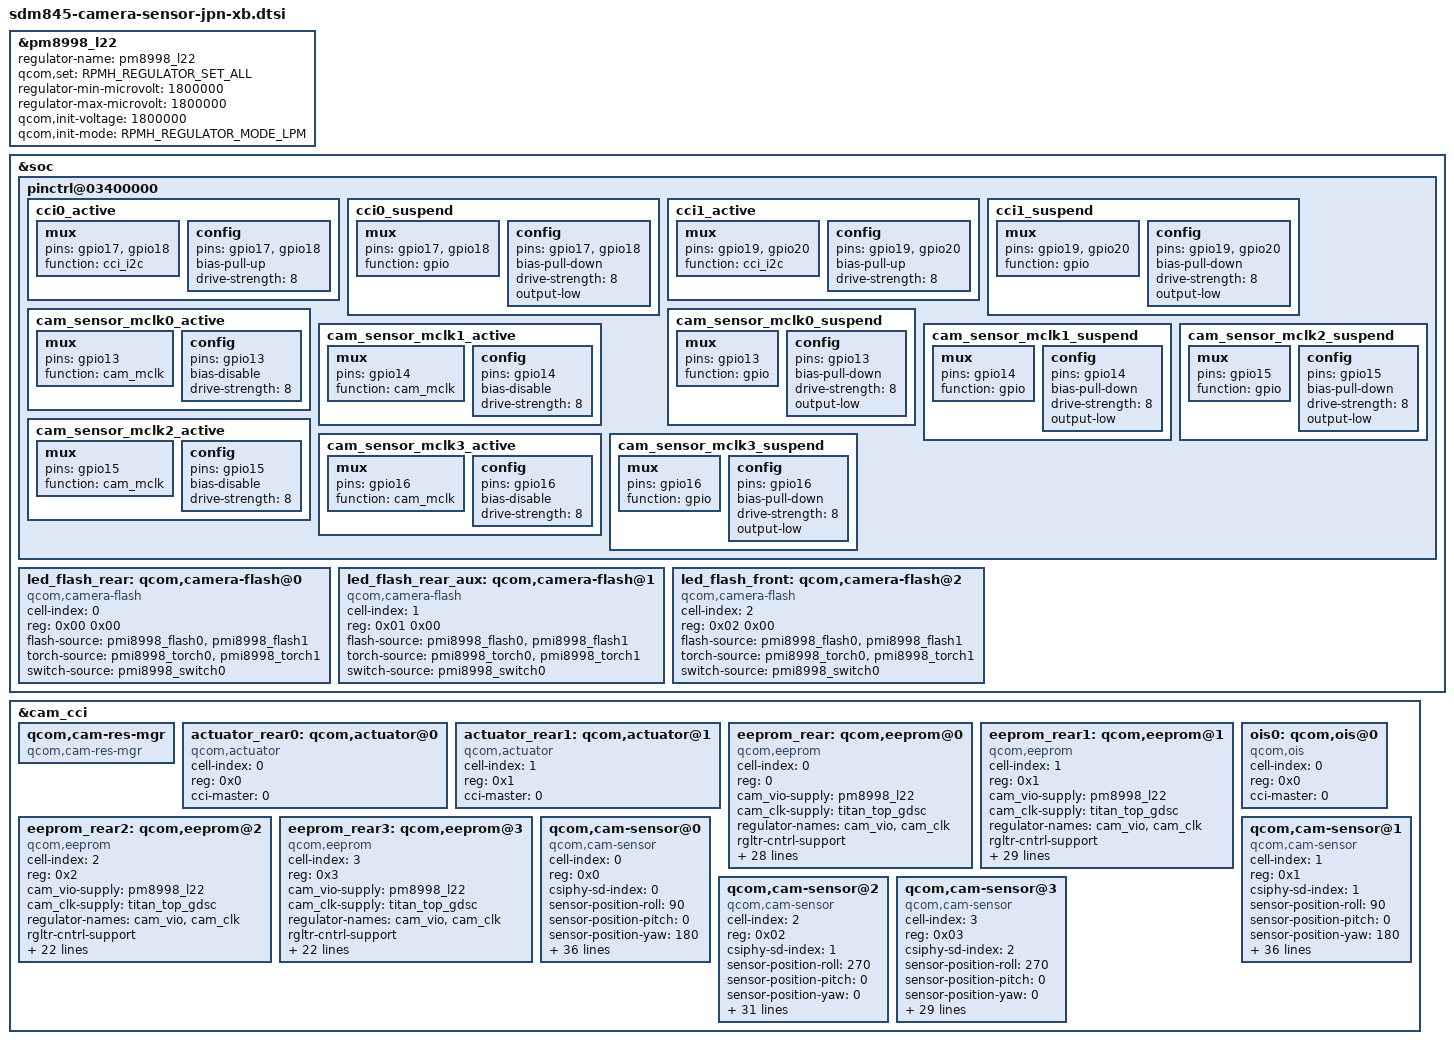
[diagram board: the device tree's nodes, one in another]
/*
 * Copyright (c) 2017, The Linux Foundation. All rights reserved.
 *
 * This program is free software; you can redistribute it and/or modify
 * it under the terms of the GNU General Public License version 2 and
 * only version 2 as published by the Free Software Foundation.
 *
 * This program is distributed in the hope that it will be useful,
 * but WITHOUT ANY WARRANTY; without even the implied warranty of
 * MERCHANTABILITY or FITNESS FOR A PARTICULAR PURPOSE. See the
 * GNU General Public License for more details.
 */

#include <dt-bindings/regulator/qcom,rpmh-regulator.h>

&pm8998_l22 {
	regulator-name = "pm8998_l22";
	qcom,set = <RPMH_REGULATOR_SET_ALL>;
	regulator-min-microvolt = <1800000>;
	regulator-max-microvolt = <1800000>;
	qcom,init-voltage = <1800000>;
	qcom,init-mode = <RPMH_REGULATOR_MODE_LPM>;
};

&soc {
	pinctrl@03400000 {
		cci0_active {
			mux {
				/* CLK, DATA */
				pins = "gpio17","gpio18"; // Only 2
				function = "cci_i2c";
			};

			config {
				pins = "gpio17","gpio18";
				bias-pull-up; /* PULL UP*/
				drive-strength = <8>; /* 2 MA */
			};
		};

		cci0_suspend {
			mux {
				/* CLK, DATA */
				pins = "gpio17","gpio18";
				function = "gpio";
			};

			config {
				pins = "gpio17","gpio18";
				bias-pull-down; /* PULL DOWN */
				drive-strength = <8>; /* 2 MA */
				output-low; /*HTC ADD*/
			};
		};

		cci1_active {
			mux {
				/* CLK, DATA */
				pins = "gpio19","gpio20";
				function = "cci_i2c";
			};

			config {
				pins = "gpio19","gpio20";
				bias-pull-up; /* PULL UP*/
				drive-strength = <8>; /* 2 MA */
			};
		};

		cci1_suspend {
			mux {
				/* CLK, DATA */
				pins = "gpio19","gpio20";
				function = "gpio";
			};

			config {
				pins = "gpio19","gpio20";
				bias-pull-down; /* PULL DOWN */
				drive-strength = <8>; /* 2 MA */
				output-low; /*HTC ADD*/
			};
		};

		cam_sensor_mclk0_active {
			/* MCLK0 */
			mux {
				/* CLK, DATA */
				pins = "gpio13";
				function = "cam_mclk";
			};

			config {
				pins = "gpio13";
				bias-disable; /* No PULL */
				drive-strength = <8>; /* 2 MA */
			};
		};

		cam_sensor_mclk0_suspend {
			/* MCLK0 */
			mux {
				/* CLK, DATA */
				pins = "gpio13";
				function = "gpio";
			};

			config {
				pins = "gpio13";
				bias-pull-down; /* PULL DOWN */
				drive-strength = <8>; /* 2 MA */
				output-low; /*HTC ADD*/
			};
		};

		cam_sensor_mclk1_active {
			/* MCLK1 */
			mux {
				/* CLK, DATA */
				pins = "gpio14";
				function = "cam_mclk";
			};

			config {
				pins = "gpio14";
				bias-disable; /* No PULL */
				drive-strength = <8>; /* 2 MA */
			};
		};

		cam_sensor_mclk1_suspend {
			/* MCLK1 */
			mux {
				/* CLK, DATA */
				pins = "gpio14";
				function = "gpio";
			};

			config {
				pins = "gpio14";
				bias-pull-down; /* PULL DOWN */
				drive-strength = <8>; /* 2 MA */
				output-low; /*HTC ADD*/
			};
		};
		cam_sensor_mclk2_active {
			/* MCLK2 */
			mux {
				/* CLK, DATA */
				pins = "gpio15";
				function = "cam_mclk";
			};

			config {
				pins = "gpio15";
				bias-disable; /* No PULL */
				drive-strength = <8>; /* 2 MA */
			};
		};

		cam_sensor_mclk2_suspend {
			/* MCLK2 */
			mux {
				/* CLK, DATA */
				pins = "gpio15";
				function = "gpio";
			};

			config {
				pins = "gpio15";
				bias-pull-down; /* PULL DOWN */
				drive-strength = <8>; /* 2 MA */
				output-low; /*HTC ADD*/
			};
		};
		cam_sensor_mclk3_active {
			/* MCLK3 */
			mux {
				pins = "gpio16";
				function = "cam_mclk";
			};

			config {
				pins = "gpio16";
				bias-disable; /* No PULL */
				drive-strength = <8>; /* 2 MA */
			};
		};
		cam_sensor_mclk3_suspend {
			/* MCLK3 */
			mux {
				/* CLK, DATA */
				pins = "gpio16";
				function = "gpio";
			};

			config {
				pins = "gpio16";
				bias-pull-down; /* PULL DOWN */
				drive-strength = <8>; /* 2 MA */
				output-low; /*HTC ADD*/
			};
		};
	};
	led_flash_rear: qcom,camera-flash@0 {
		/* REAR FLASH */
		cell-index = <0>;
		reg = <0x00 0x00>;
		compatible = "qcom,camera-flash";
		flash-source = <&pmi8998_flash0 &pmi8998_flash1>;
		torch-source = <&pmi8998_torch0 &pmi8998_torch1>;
		switch-source = <&pmi8998_switch0>;
		status = "ok";
	};

	led_flash_rear_aux: qcom,camera-flash@1 {
		cell-index = <1>;
		reg = <0x01 0x00>;
		compatible = "qcom,camera-flash";
		flash-source = <&pmi8998_flash0 &pmi8998_flash1>;
		torch-source = <&pmi8998_torch0 &pmi8998_torch1>;
		switch-source = <&pmi8998_switch0>;
		status = "ok";
	};

	led_flash_front: qcom,camera-flash@2 {
		cell-index = <2>;
		reg = <0x02 0x00>;
		compatible = "qcom,camera-flash";
		flash-source = <&pmi8998_flash0 &pmi8998_flash1>;
		torch-source = <&pmi8998_torch0 &pmi8998_torch1>;
		switch-source = <&pmi8998_switch0>;
		status = "ok";
	};
};

&cam_cci {
	qcom,cam-res-mgr {
		compatible = "qcom,cam-res-mgr";
		status = "ok";
	};

	actuator_rear0: qcom,actuator@0 {
		cell-index = <0>;
		reg = <0x0>;
		compatible = "qcom,actuator";
		cci-master = <0>;
	};
	actuator_rear1: qcom,actuator@1 {
		cell-index = <1>;
		reg = <0x1>;
		compatible = "qcom,actuator";
		cci-master = <0>;
	};
	eeprom_rear: qcom,eeprom@0 {
		cell-index = <0>;
		reg = <0>;
		compatible = "qcom,eeprom";
		cam_vio-supply = <&pm8998_l22>;
		cam_clk-supply = <&titan_top_gdsc>;
		regulator-names = "cam_vio", "cam_clk";
		rgltr-cntrl-support;
		rgltr-min-voltage = <1800000 0>;
		rgltr-max-voltage = <1800000 0>;
		rgltr-load-current = <0 0>;
		gpio-no-mux = <0>;
		pinctrl-names = "cam_default", "cam_suspend";
		pinctrl-0 = <&cam_sensor_mclk0_active>;
		pinctrl-1 = <&cam_sensor_mclk0_suspend>;
		gpios = <&tlmm 13 0>,
			<&tca6418_qup3 15 0>,
			<&tca6418_qup3 14 0>,
			<&tca6418_qup3 10 0>,
			<&tca6418_qup3 11 0>,
			<&tca6418_qup3 12 0>,
			<&tca6418_qup3 13 0>,
			<&tca6418_qup3 17 0>;
		gpio-reset = <1>;
		gpio-vdig = <2>;
		gpio-vana = <3>;
		gpio-vaf = <4>;
		gpio-custom1 = <5>;
		gpio-custom2 = <6>;
		gpio-standby = <7>;
		gpio-req-tbl-num = <0 1 2 3 4 5 6 7>;
		gpio-req-tbl-flags = <1 0 0 0 0 0 0 0>;
		gpio-req-tbl-label = "CAMIF_MCLK0",
					"CAM0_RESET0",
					"CAM0_VDIG",
					"CAM0_VANA",
					"CAM0_VAF",
					"CAM0_A1V8",
					"CAM0_DRV",
					"CAM_1V1_EN";
		sensor-position = <0>;
		sensor-mode = <0>;
		cci-master = <0>;
		status = "ok";
		clocks = <&clock_camcc CAM_CC_MCLK0_CLK>;
		clock-names = "cam_clk";
		clock-cntl-level = "turbo";
		clock-rates = <24000000>;
	};
	eeprom_rear1: qcom,eeprom@1 {
		cell-index = <1>;
		reg = <0x1>;
		compatible = "qcom,eeprom";
		cam_vio-supply = <&pm8998_l22>;
		cam_clk-supply = <&titan_top_gdsc>;
		regulator-names = "cam_vio", "cam_clk";
		rgltr-cntrl-support;
		rgltr-min-voltage = <1800000 0>;
		rgltr-max-voltage = <1800000 0>;
		rgltr-load-current = <0 0>;
		gpio-no-mux = <0>;
		pinctrl-names = "cam_default", "cam_suspend";
		pinctrl-0 = <&cam_sensor_mclk1_active>;
		pinctrl-1 = <&cam_sensor_mclk1_suspend>;
		gpios = <&tlmm 14 0>,
			<&tca6418_qup3 4 0>,
			<&tca6418_qup3 0 0>,
			<&tca6418_qup3 1 0>,
			<&tca6418_qup3 3 0>,
			<&tlmm 11 0>,
			<&tca6418_qup3 2 0>,
			<&tca6418_qup3 13 0>,
			<&tca6418_qup3 17 0>;
		gpio-reset = <1>;
		gpio-vdig = <2>;
		gpio-vana = <3>;
		gpio-custom1 = <4>;
		gpio-custom2 = <5>;
		gpio-vaf = <6>;
		gpio-af-pwdm = <7>;
		gpio-standby = <8>;
		gpio-req-tbl-num = <0 1 2 3 4 5 6 7 8>;
		gpio-req-tbl-flags = <1 0 0 0 0 0 0 0 0>;
		gpio-req-tbl-label = "CAMIF_MCLK1",
					"CAM1_RESET1",
					"CAM1_VDIG",
					"CAM1_VANA",
					"CAM1_A1V8",
					"CAM1_SID",
					"CAM1_VAF",
					"CAM1_DRV",
					"CAM_1V1_EN";
		sensor-position = <0>;
		sensor-mode = <0>;
		cci-master = <0>;
		status = "ok";
		clocks = <&clock_camcc CAM_CC_MCLK1_CLK>;
		clock-names = "cam_clk";
		clock-cntl-level = "turbo";
		clock-rates = <24000000>;
	};
	eeprom_rear2: qcom,eeprom@2 {
		cell-index = <2>;
		reg = <0x2>;
		compatible = "qcom,eeprom";
		cam_vio-supply = <&pm8998_l22>;
		cam_clk-supply = <&titan_top_gdsc>;
		regulator-names = "cam_vio", "cam_clk";
		rgltr-cntrl-support;
		rgltr-min-voltage = <1800000 0>;
		rgltr-max-voltage = <1800000 0>;
		rgltr-load-current = <0 0>;
		gpio-no-mux = <0>;
		pinctrl-names = "cam_default", "cam_suspend";
		pinctrl-0 = <&cam_sensor_mclk3_active>;
		pinctrl-1 = <&cam_sensor_mclk3_suspend>;
		gpios = <&tlmm 16 0>,
			<&tca6418_qup3 9 0>,
			<&tca6418_qup3 16 0>,
			<&tca6418_qup3 8 0>,
			<&tca6418_qup3 17 0>;
		gpio-reset = <1>;
		gpio-vdig = <2>;
		gpio-vana = <3>;
		gpio-standby = <4>;
		gpio-req-tbl-num = <0 1 2 3 4>;
		gpio-req-tbl-flags = <1 0 0 0 4>;
		gpio-req-tbl-label = "CAMIF_MCLK3",
					"CAM_RESET3",
					"CAM3_VDIG",
					"CAM3_VANA",
					"CAM_1V1_EN";
		sensor-mode = <0>;
		cci-master = <1>;
		status = "ok";
		clocks = <&clock_camcc CAM_CC_MCLK3_CLK>;
		clock-names = "cam_clk";
		clock-cntl-level = "turbo";
		clock-rates = <24000000>;
	};
	eeprom_rear3: qcom,eeprom@3 {
		cell-index = <3>;
		reg = <0x3>;
		compatible = "qcom,eeprom";
		cam_vio-supply = <&pm8998_l22>;
		cam_clk-supply = <&titan_top_gdsc>;
		regulator-names = "cam_vio", "cam_clk";
		rgltr-cntrl-support;
		rgltr-min-voltage = <1800000 0>;
		rgltr-max-voltage = <1800000 0>;
		rgltr-load-current = <0 0>;
		gpio-no-mux = <0>;
		pinctrl-names = "cam_default", "cam_suspend";
		pinctrl-0 = <&cam_sensor_mclk3_active>;
		pinctrl-1 = <&cam_sensor_mclk3_suspend>;
		gpios = <&tlmm 16 0>,
			<&tca6418_qup3 9 0>,
			<&tca6418_qup3 16 0>,
			<&tca6418_qup3 8 0>,
			<&tca6418_qup3 17 0>;
		gpio-reset = <1>;
		gpio-vdig = <2>;
		gpio-vana = <3>;
		gpio-standby = <4>;
		gpio-req-tbl-num = <0 1 2 3 4>;
		gpio-req-tbl-flags = <1 0 0 0 4>;
		gpio-req-tbl-label = "CAMIF_MCLK3",
					"CAM_RESET3",
					"CAM3_VDIG",
					"CAM3_VANA",
					"CAM_1V1_EN";
		sensor-mode = <0>;
		cci-master = <1>;
		status = "ok";
		clocks = <&clock_camcc CAM_CC_MCLK3_CLK>;
		clock-names = "cam_clk";
		clock-cntl-level = "turbo";
		clock-rates = <24000000>;
	};
	ois0: qcom,ois@0 {
		cell-index = <0>;
		reg = <0x0>;
		compatible = "qcom,ois";
		cci-master = <0>;
	};
	qcom,cam-sensor@0 {
		cell-index = <0>;
		compatible = "qcom,cam-sensor";
		reg = <0x0>;
		csiphy-sd-index = <0>;
		sensor-position-roll = <90>;
		sensor-position-pitch = <0>;
		sensor-position-yaw = <180>;
		actuator-src = <&actuator_rear0>;
		led-flash-src = <&led_flash_rear>;
		eeprom-src = <&eeprom_rear>;
		ois-src = <&ois0>;
		qcom,camera-ver = <3>;
		cam_vio-supply = <&pm8998_l22>;
		cam_clk-supply = <&titan_top_gdsc>;
		regulator-names = "cam_vio", "cam_clk";
		rgltr-cntrl-support;
		rgltr-min-voltage = <1800000 0>;
		rgltr-max-voltage = <1800000 0>;
		rgltr-load-current = <0 0>;
		gpio-no-mux = <0>;
		pinctrl-names = "cam_default", "cam_suspend";
		pinctrl-0 = <&cam_sensor_mclk0_active>;
		pinctrl-1 = <&cam_sensor_mclk0_suspend>;
		gpios = <&tlmm 13 0>,
			<&tca6418_qup3 15 0>,
			<&tca6418_qup3 14 0>,
			<&tca6418_qup3 10 0>,
			<&tca6418_qup3 11 0>,
			<&tca6418_qup3 12 0>,
			<&tca6418_qup3 13 0>,
			<&tca6418_qup3 17 0>;
		gpio-reset = <1>;
		gpio-vdig = <2>;
		gpio-vana = <3>;
		gpio-vaf = <4>;
		gpio-custom1 = <5>;
		gpio-custom2 = <6>;
		gpio-standby = <7>;
		gpio-req-tbl-num = <0 1 2 3 4 5 6 7>;
		gpio-req-tbl-flags = <1 0 0 0 0 0 0 0>;
		gpio-req-tbl-label = "CAMIF_MCLK0",
					"CAM0_RESET0",
					"CAM0_VDIG",
					"CAM0_VANA",
					"CAM0_VAF",
					"CAM0_A1V8",
					"CAM0_DRV",
					"CAM_1V1_EN";
		sensor-mode = <0>;
		cci-master = <0>;
		status = "ok";
		clocks = <&clock_camcc CAM_CC_MCLK0_CLK>;
		clock-names = "cam_clk";
		clock-cntl-level = "turbo";
		clock-rates = <24000000>;
	};

	qcom,cam-sensor@1 {
		cell-index = <1>;
		compatible = "qcom,cam-sensor";
		reg = <0x1>;
		csiphy-sd-index = <1>;
		sensor-position-roll = <90>;
		sensor-position-pitch = <0>;
		sensor-position-yaw = <180>;
		actuator-src = <&actuator_rear1>;
		eeprom-src = <&eeprom_rear1>;
		led-flash-src = <&led_flash_rear_aux>;
		qcom,camera-ver = <3>;
		cam_vio-supply = <&pm8998_l22>;
		cam_clk-supply = <&titan_top_gdsc>;
		regulator-names = "cam_vio", "cam_clk";
		rgltr-cntrl-support;
		rgltr-min-voltage = <1800000 0>;
		rgltr-max-voltage = <1800000 0>;
		rgltr-load-current = <0 0>;
		gpio-no-mux = <0>;
		pinctrl-names = "cam_default", "cam_suspend";
		pinctrl-0 = <&cam_sensor_mclk1_active>;
		pinctrl-1 = <&cam_sensor_mclk1_suspend>;
		gpios = <&tlmm 14 0>,
			<&tca6418_qup3 4 0>,
			<&tca6418_qup3 0 0>,
			<&tca6418_qup3 1 0>,
			<&tca6418_qup3 3 0>,
			<&tlmm 11 0>,
			<&tca6418_qup3 2 0>,
			<&tca6418_qup3 13 0>,
			<&tca6418_qup3 17 0>;
		gpio-reset = <1>;
		gpio-vdig = <2>;
		gpio-vana = <3>;
		gpio-custom1 = <4>;
		gpio-custom2 = <5>;
		gpio-vaf = <6>;
		gpio-af-pwdm = <7>;
		gpio-standby = <8>;
		gpio-req-tbl-num = <0 1 2 3 4 5 6 7 8>;
		gpio-req-tbl-flags = <1 0 0 0 0 0 0 0 0>;
		gpio-req-tbl-label = "CAMIF_MCLK1",
					"CAM1_RESET1",
					"CAM1_VDIG",
					"CAM1_VANA",
					"CAM1_A1V8",
					"CAM1_SID",
					"CAM1_VAF",
					"CAM1_DRV",
					"CAM_1V1_EN";
		sensor-mode = <0>;
		cci-master = <0>;
		status = "ok";
		clocks = <&clock_camcc CAM_CC_MCLK1_CLK>;
		clock-names = "cam_clk";
		clock-cntl-level = "turbo";
		clock-rates = <24000000>;
	};

	qcom,cam-sensor@2 {
		cell-index = <2>;
		compatible = "qcom,cam-sensor";
		reg = <0x02>;
		csiphy-sd-index = <1>;
		sensor-position-roll = <270>;
		sensor-position-pitch = <0>;
		sensor-position-yaw = <0>;
		qcom,camera-ver = <3>;
		eeprom-src = <&eeprom_rear2>;
		cam_vio-supply = <&pm8998_l22>;
		cam_clk-supply = <&titan_top_gdsc>;
		regulator-names = "cam_vio", "cam_clk";
		rgltr-cntrl-support;
		rgltr-min-voltage = <1800000 0>;
		rgltr-max-voltage = <1800000 0>;
		rgltr-load-current = <0 0>;
		gpio-no-mux = <0>;
		pinctrl-names = "cam_default", "cam_suspend";
		pinctrl-0 = <&cam_sensor_mclk2_active>;
		pinctrl-1 = <&cam_sensor_mclk2_suspend>;
		gpios = <&tlmm 15 0>,
			<&tca6418_qup3 7 0>,
			<&tca6418_qup3 5 0>,
			<&tca6418_qup3 6 0>,
			<&tca6418_qup3 17 0>,
			<&tlmm 133 0>,
			<&tca6418_qup3 13 0>;
		gpio-reset = <1>;
		gpio-vdig = <2>;
		gpio-vana = <3>;
		gpio-standby = <4>;
		gpio-custom1 = <5>;
		gpio-custom2 = <6>;
		gpio-req-tbl-num = <0 1 2 3 4 5 6>;
		gpio-req-tbl-flags = <1 0 0 0 0 0 0>;
		gpio-req-tbl-label = "CAMIF_MCLK2",
					"CAM_RESET2",
					"CAM2_VDIG",
					"CAM2_VANA",
					"CAM_1V1_EN",
					"CAM_SEL_PIN",
					"CAM2_DRV";
		sensor-mode = <0>;
		cci-master = <0>;
		status = "ok";
		clocks = <&clock_camcc CAM_CC_MCLK2_CLK>;
		clock-names = "cam_clk";
		clock-cntl-level = "turbo";
		clock-rates = <24000000>;
	};

	qcom,cam-sensor@3 {
		cell-index = <3>;
		compatible = "qcom,cam-sensor";
		reg = <0x03>;
		csiphy-sd-index = <2>;
		sensor-position-roll = <270>;
		sensor-position-pitch = <0>;
		sensor-position-yaw = <0>;
		led-flash-src = <&led_flash_front>;
		qcom,camera-ver = <3>;
		eeprom-src = <&eeprom_rear3>;
		cam_vio-supply = <&pm8998_l22>;
		cam_clk-supply = <&titan_top_gdsc>;
		regulator-names = "cam_vio", "cam_clk";
		rgltr-cntrl-support;
		rgltr-min-voltage = <1800000 0>;
		rgltr-max-voltage = <1800000 0>;
		rgltr-load-current = <0 0>;
		gpio-no-mux = <0>;
		pinctrl-names = "cam_default", "cam_suspend";
		pinctrl-0 = <&cam_sensor_mclk3_active>;
		pinctrl-1 = <&cam_sensor_mclk3_suspend>;
		gpios = <&tlmm 16 0>,
			<&tca6418_qup3 9 0>,
			<&tca6418_qup3 16 0>,
			<&tca6418_qup3 8 0>,
			<&tca6418_qup3 17 0>;
		gpio-reset = <1>;
		gpio-vdig = <2>;
		gpio-vana = <3>;
		gpio-standby = <4>;
		gpio-req-tbl-num = <0 1 2 3 4>;
		gpio-req-tbl-flags = <1 0 0 0 4>;
		gpio-req-tbl-label = "CAMIF_MCLK3",
					"CAM_RESET3",
					"CAM3_VDIG",
					"CAM3_VANA",
					"CAM_1V1_EN";
		sensor-mode = <0>;
		cci-master = <1>;
		status = "ok";
		clocks = <&clock_camcc CAM_CC_MCLK3_CLK>;
		clock-names = "cam_clk";
		clock-cntl-level = "turbo";
		clock-rates = <24000000>;
	};
};
